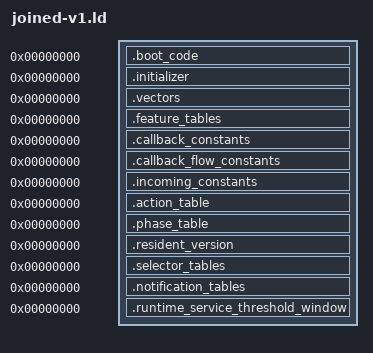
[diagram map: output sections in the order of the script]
OUTPUT_ARCH(riscv)
SECTIONS
{
 .boot_code 0 : SUBALIGN(2) { *(.boot_code)
  *(.text.tsl9_settings_state_inputs_provider_a00c)
  *(.text.tsl9_runtime_service_links_block_a016)
  *(.text.tsl9_runtime_service_links_block_a018)
  *(.text.tsl9_runtime_service_links_block_a01a)
  *(.text.tsl9_runtime_service_links_block_a01c)
  *(.text.tsl9_runtime_service_links_block_a022)
  *(.text.tsl9_settings_state_inputs_provider_b520)
  *(.text.tsl9_runtime_service_links_block_b530)
  *(.text.tsl9_runtime_service_links_block_b540)
  *(.text.tsl9_runtime_service_links_block_b548)
  *(.text.tsl9_runtime_service_links_block_b54a)
  *(.text.tsl9_runtime_service_links_block_b54e)
  *(.text.tsl9_runtime_service_links_block_b550)
  *(.text.tsl9_runtime_service_links_block_b56a)
  *(.text.tsl9_runtime_service_links_block_b570)
  *(.text.tsl9_runtime_service_links_entry_b5c6)
  *(.text.tsl9_settings_state_inputs_provider_bce0)
  *(.text.tsl9_settings_state_inputs_provider_cc54)
  *(.text.tsl9_record_dispatch_provider_cc82)
  *(.text.tsl9_runtime_service_links_entry_e0ba)
  *(.text.tsl9_runtime_service_links_block_e0c4)
  *(.text.tsl9_runtime_service_links_block_e0c8)
  *(.text.tsl9_runtime_service_links_block_e0ce)
  *(.text.tsl9_runtime_service_links_block_e0d2)
  *(.text.tsl9_runtime_service_links_block_e0d6)
  *(.text.tsl9_runtime_service_links_block_e0da)
  *(.text.tsl9_runtime_service_links_block_e0de)
  *(.text.tsl9_runtime_service_links_block_e0e2)
  *(.text.tsl9_runtime_service_links_block_e0e6)
  *(.text.tsl9_runtime_service_links_block_e0e8)
  *(.text.tsl9_runtime_service_links_block_e0f0)
  *(.text.tsl9_runtime_service_links_block_e0f4)
  *(.text.tsl9_runtime_service_links_block_e0f6)
  *(.text.tsl9_runtime_service_links_block_e0fa)
  *(.text.tsl9_runtime_service_links_block_e0fe)
  *(.text.tsl9_runtime_service_links_block_e100)
  *(.text.tsl9_runtime_service_links_block_e106)
  *(.text.tsl9_runtime_service_links_block_e10a)
  *(.text.tsl9_runtime_service_links_block_e10c)
  *(.text.tsl9_runtime_service_links_block_e116)
  *(.text.tsl9_runtime_service_links_block_e11a)
  *(.text.tsl9_runtime_service_links_block_e11c)
  *(.text.tsl9_runtime_service_links_block_e122)
  *(.text.tsl9_runtime_service_links_block_e126)
  *(.text.tsl9_runtime_service_links_block_e128)
  *(.text.tsl9_runtime_service_links_block_e130)
  *(.text.tsl9_runtime_service_links_block_e134)
  *(.text.tsl9_runtime_service_links_block_e136)
  *(.text.tsl9_runtime_service_links_block_e13e)
  *(.text.tsl9_runtime_service_links_block_e142)
  *(.text.tsl9_runtime_service_links_block_e144)
  *(.text.tsl9_runtime_service_links_block_e14c)
  *(.text.tsl9_runtime_service_links_block_e150)
  *(.text.tsl9_runtime_service_links_block_e152)
  *(.text.tsl9_runtime_service_links_block_e15a)
  *(.text.tsl9_runtime_service_links_block_e15e)
  *(.text.tsl9_runtime_service_links_block_e160)
  *(.text.tsl9_runtime_service_links_block_e168)
  *(.text.tsl9_runtime_service_links_block_e16c)
  *(.text.tsl9_runtime_service_links_block_e16e)
  *(.text.tsl9_runtime_service_links_block_e176)
  *(.text.tsl9_runtime_service_links_block_e17a)
  *(.text.tsl9_runtime_service_links_block_e17c)
  *(.text.tsl9_runtime_service_links_block_e184)
  *(.text.tsl9_runtime_service_links_block_e188)
  *(.text.tsl9_runtime_service_links_block_e18a)
  *(.text.tsl9_runtime_service_links_block_e190)
  *(.text.tsl9_runtime_service_links_block_e194)
  *(.text.tsl9_runtime_service_links_block_e196)
  *(.text.tsl9_runtime_service_links_block_e19c)
  *(.text.tsl9_record_dispatch_provider_e1a6)
  *(.text.tsl9_runtime_service_links_block_e1b6)
  *(.text.tsl9_runtime_service_links_block_e1c0)
  *(.text.tsl9_runtime_service_links_block_e1c6)
  *(.text.tsl9_runtime_service_links_block_e1ca)
  *(.text.tsl9_runtime_service_links_block_e1cc)
  *(.text.tsl9_runtime_service_links_block_e1d0)
  *(.text.tsl9_runtime_service_links_block_e1e4)
  *(.text.tsl9_runtime_service_links_block_e1ee)
  *(.text.tsl9_runtime_service_links_block_e1f2)
  *(.text.tsl9_runtime_service_links_block_e1fe)
  *(.text.tsl9_runtime_service_links_block_e20a)
  *(.text.tsl9_settings_state_inputs_provider_e20c)
  *(.text.tsl9_settings_state_inputs_provider_f666)
  *(.text.tsl9_record_dispatch_provider_f67e)
  *(.text.tsl9_record_dispatch_provider_f78c)
  *(.text.tsl9_record_dispatch_provider_f7d2)
  *(.text.tsl9_settings_state_inputs_provider_f9ec)
  *(.text.tsl9_runtime_service_links_block_f9fa)
  *(.text.tsl9_runtime_service_links_block_fa18)
  *(.text.tsl9_runtime_service_links_block_fa22)
  *(.text.tsl9_runtime_service_links_entry_fa3c)
  *(.text.tsl9_runtime_service_links_entry_fa4a)
  *(.text.tsl9_runtime_service_links_entry_fafe)
  *(.text.tsl9_settings_state_inputs_provider_17bc4)
  *(.text.tsl9_runtime_service_links_block_17bc6)
  *(.text.tsl9_runtime_service_links_block_17bd6)
  *(.text.tsl9_runtime_service_links_block_17be2)
 }
 .initializer 0 : SUBALIGN(4) { *(.initializer) }
 .vectors 0 : SUBALIGN(4) { *(.vectors) }
 .feature_tables 0 : SUBALIGN(4) { *(.feature_tables) }
 .callback_constants 0 : SUBALIGN(4) { *(.callback_constants) }
 .callback_flow_constants 0 : SUBALIGN(4) { *(.callback_flow_constants) }
 .incoming_constants 0 : SUBALIGN(4) { *(.incoming_constants) }
 .action_table 0 : SUBALIGN(4) { *(.action_table) }
 .phase_table 0 : SUBALIGN(4) { *(.phase_table) }
 .resident_version 0 : SUBALIGN(4) { *(.resident_version) }
 .selector_tables 0 : SUBALIGN(1) {
  *(.rodata.tsl9_feature_state_records_static_data_1a4e4)
  *(.rodata.tsl9_feature_state_records_static_data_1a518)
  *(.rodata.tsl9_feature_state_records_static_data_1a528)
  *(.rodata.tsl9_feature_state_records_static_data_1a538)
 }
 .notification_tables 0 : SUBALIGN(4) {
  *(.rodata.tsl9_selector_notifications_table_1a13c)
  *(.rodata.tsl9_selector_notifications_table_1a150)
  *(.rodata.tsl9_selector_notifications_table_1a1c8)
  *(.rodata.tsl9_selector_notifications_table_1a314)
  *(.rodata.tsl9_selector_notifications_table_1a33c)
 }
 .runtime_service_threshold_window 0 : SUBALIGN(1) { *(.rodata.tsl9_runtime_service_threshold_bytes_1ab58) }
 /DISCARD/ : { *(.comment) *(.riscv.attributes) *(.llvm_addrsig) }
}
